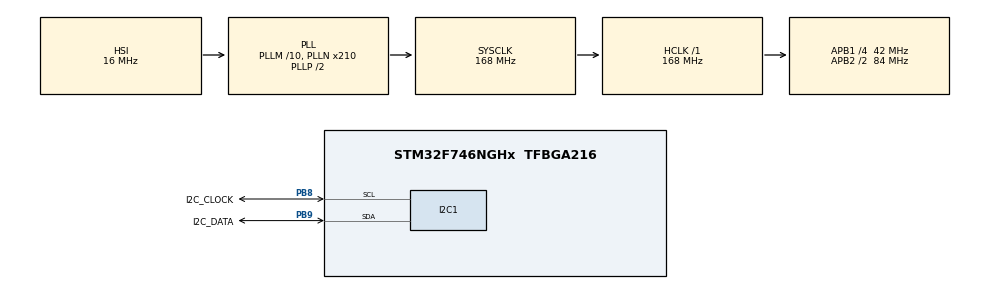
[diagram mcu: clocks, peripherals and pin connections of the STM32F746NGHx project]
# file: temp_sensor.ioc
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Mcu.Family=STM32F7
Mcu.Name=STM32F746NGHx
Mcu.Package=TFBGA216
NVIC.PriorityGroup=NVIC_PRIORITYGROUP_4
NVIC.TIM8_TRG_COM_TIM14_IRQn=true\:0\:0\:false\:false\:true\:false\:true
NVIC.TimeBase=TIM8_TRG_COM_TIM14_IRQn
NVIC.TimeBaseIP=TIM14
PA13.Mode=Serial_Wire
PA13.Signal=SYS_JTMS-SWDIO
PA14.Mode=Serial_Wire
PA14.Signal=SYS_JTCK-SWCLK
PB8.GPIO_Label=I2C_CLOCK
PB8.GPIO_Speed=GPIO_SPEED_FREQ_VERY_HIGH
PB8.Mode=I2C
PB8.Signal=I2C1_SCL
PB9.GPIO_Label=I2C_DATA
PB9.Mode=I2C
PB9.Signal=I2C1_SDA
PC14/OSC32_IN.Mode=LSE-External-Oscillator
PC14/OSC32_IN.Signal=RCC_OSC32_IN
PC15/OSC32_OUT.Mode=LSE-External-Oscillator
PC15/OSC32_OUT.Signal=RCC_OSC32_OUT
PH0/OSC_IN.Mode=HSE-External-Clock-Source
PH0/OSC_IN.Signal=RCC_OSC_IN
PH1/OSC_OUT.Mode=HSE-External-Clock-Source
PH1/OSC_OUT.Signal=RCC_OSC_OUT
ProjectManager.HeapSize=0x200
ProjectManager.StackSize=0x400
ProjectManager.TargetToolchain=STM32CubeIDE
RCC.AHBFreq_Value=168000000
RCC.APB1CLKDivider=RCC_HCLK_DIV4
RCC.APB1Freq_Value=42000000
RCC.APB1TimFreq_Value=84000000
RCC.APB2CLKDivider=RCC_HCLK_DIV2
RCC.APB2Freq_Value=84000000
RCC.APB2TimFreq_Value=168000000
RCC.CortexFreq_Value=168000000
RCC.HCLKFreq_Value=168000000
RCC.HSE_VALUE=25000000
RCC.HSI_VALUE=16000000
RCC.PLLM=10
RCC.PLLN=210
RCC.PLLSourceVirtual=RCC_PLLSOURCE_HSI
RCC.SYSCLKFreq_VALUE=168000000
RCC.SYSCLKSource=RCC_SYSCLKSOURCE_PLLCLK
RCC.USBFreq_Value=168000000
RCC.VCOOutputFreq_Value=336000000
VP_SYS_VS_tim14.Mode=TIM14
board=STM32F746G-DISCO

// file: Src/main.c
/* USER CODE BEGIN Header */
/**
  ******************************************************************************
  * @file           : main.c
  * @brief          : Main program body
  ******************************************************************************
  * @attention
  *
  * <h2><center>&copy; Copyright (c) 2019 STMicroelectronics.
  * All rights reserved.</center></h2>
  *
  * This software component is licensed by ST under BSD 3-Clause license,
  * the "License"; You may not use this file except in compliance with the
  * License. You may obtain a copy of the License at:
  *                        opensource.org/licenses/BSD-3-Clause
  *
  ******************************************************************************
  */
/* USER CODE END Header */

#include "main.h"

/* USER CODE BEGIN PD */
#define TEMP_SENSOR_ADDRESS (0b1001000 << 1)
/* USER CODE END PD */

I2C_HandleTypeDef hi2c1;

/* USER CODE BEGIN PV */
uint8_t read_temp_reg = 0;
uint8_t read_temp_val;
/* USER CODE END PV */

void SystemClock_Config(void);
static void MX_GPIO_Init(void);
static void MX_I2C1_Init(void);

int main(void)
{

  /* MCU Configuration--------------------------------------------------------*/

  /* Reset of all peripherals, Initializes the Flash interface and the Systick. */
  HAL_Init();

  /* Configure the system clock */
  SystemClock_Config();

  /* Initialize all configured peripherals */
  MX_GPIO_Init();
  MX_I2C1_Init();

  /* Infinite loop */
  /* USER CODE BEGIN WHILE */
  while (1)
  {

	  HAL_Delay(1000);

	  HAL_I2C_Master_Transmit(&hi2c1, TEMP_SENSOR_ADDRESS, &read_temp_reg, sizeof(read_temp_reg), 100);
	  HAL_I2C_Master_Receive(&hi2c1, TEMP_SENSOR_ADDRESS, &read_temp_val, sizeof(read_temp_val), 100);

      printf("Temperature: %d", read_temp_val);

    /* USER CODE END WHILE */

  }
}

void SystemClock_Config(void)
{
  RCC_OscInitTypeDef RCC_OscInitStruct = {0};
  RCC_ClkInitTypeDef RCC_ClkInitStruct = {0};
  RCC_PeriphCLKInitTypeDef PeriphClkInitStruct = {0};

  /** Configure LSE Drive Capability
  */
  HAL_PWR_EnableBkUpAccess();
  /** Configure the main internal regulator output voltage
  */
  __HAL_RCC_PWR_CLK_ENABLE();
  __HAL_PWR_VOLTAGESCALING_CONFIG(PWR_REGULATOR_VOLTAGE_SCALE2);
  /** Initializes the CPU, AHB and APB busses clocks
  */
  RCC_OscInitStruct.OscillatorType = RCC_OSCILLATORTYPE_HSI;
  RCC_OscInitStruct.HSIState = RCC_HSI_ON;
  RCC_OscInitStruct.HSICalibrationValue = RCC_HSICALIBRATION_DEFAULT;
  RCC_OscInitStruct.PLL.PLLState = RCC_PLL_ON;
  RCC_OscInitStruct.PLL.PLLSource = RCC_PLLSOURCE_HSI;
  RCC_OscInitStruct.PLL.PLLM = 10;
  RCC_OscInitStruct.PLL.PLLN = 210;
  RCC_OscInitStruct.PLL.PLLP = RCC_PLLP_DIV2;
  RCC_OscInitStruct.PLL.PLLQ = 2;
  if (HAL_RCC_OscConfig(&RCC_OscInitStruct) != HAL_OK)
  {
    Error_Handler();
  }
  /** Initializes the CPU, AHB and APB busses clocks
  */
  RCC_ClkInitStruct.ClockType = RCC_CLOCKTYPE_HCLK|RCC_CLOCKTYPE_SYSCLK
                              |RCC_CLOCKTYPE_PCLK1|RCC_CLOCKTYPE_PCLK2;
  RCC_ClkInitStruct.SYSCLKSource = RCC_SYSCLKSOURCE_PLLCLK;
  RCC_ClkInitStruct.AHBCLKDivider = RCC_SYSCLK_DIV1;
  RCC_ClkInitStruct.APB1CLKDivider = RCC_HCLK_DIV4;
  RCC_ClkInitStruct.APB2CLKDivider = RCC_HCLK_DIV2;

  if (HAL_RCC_ClockConfig(&RCC_ClkInitStruct, FLASH_LATENCY_5) != HAL_OK)
  {
    Error_Handler();
  }
  PeriphClkInitStruct.PeriphClockSelection = RCC_PERIPHCLK_I2C1;
  PeriphClkInitStruct.I2c1ClockSelection = RCC_I2C1CLKSOURCE_PCLK1;
  if (HAL_RCCEx_PeriphCLKConfig(&PeriphClkInitStruct) != HAL_OK)
  {
    Error_Handler();
  }
}

static void MX_I2C1_Init(void)
{

  hi2c1.Instance = I2C1;
  hi2c1.Init.Timing = 0x00303D5B;
  hi2c1.Init.OwnAddress1 = 0;
  hi2c1.Init.AddressingMode = I2C_ADDRESSINGMODE_7BIT;
  hi2c1.Init.DualAddressMode = I2C_DUALADDRESS_DISABLE;
  hi2c1.Init.OwnAddress2 = 0;
  hi2c1.Init.OwnAddress2Masks = I2C_OA2_NOMASK;
  hi2c1.Init.GeneralCallMode = I2C_GENERALCALL_DISABLE;
  hi2c1.Init.NoStretchMode = I2C_NOSTRETCH_DISABLE;
  if (HAL_I2C_Init(&hi2c1) != HAL_OK)
  {
    Error_Handler();
  }
  /** Configure Analogue filter
  */
  if (HAL_I2CEx_ConfigAnalogFilter(&hi2c1, I2C_ANALOGFILTER_ENABLE) != HAL_OK)
  {
    Error_Handler();
  }
  /** Configure Digital filter
  */
  if (HAL_I2CEx_ConfigDigitalFilter(&hi2c1, 0) != HAL_OK)
  {
    Error_Handler();
  }

}

static void MX_GPIO_Init(void)
{

  /* GPIO Ports Clock Enable */
  __HAL_RCC_GPIOB_CLK_ENABLE();
  __HAL_RCC_GPIOA_CLK_ENABLE();
  __HAL_RCC_GPIOC_CLK_ENABLE();
  __HAL_RCC_GPIOH_CLK_ENABLE();

}

void HAL_TIM_PeriodElapsedCallback(TIM_HandleTypeDef *htim)
{
  if (htim->Instance == TIM14) {
    HAL_IncTick();
  }
}

void Error_Handler(void)
{
}

/************************ (C) COPYRIGHT STMicroelectronics *****END OF FILE****/
